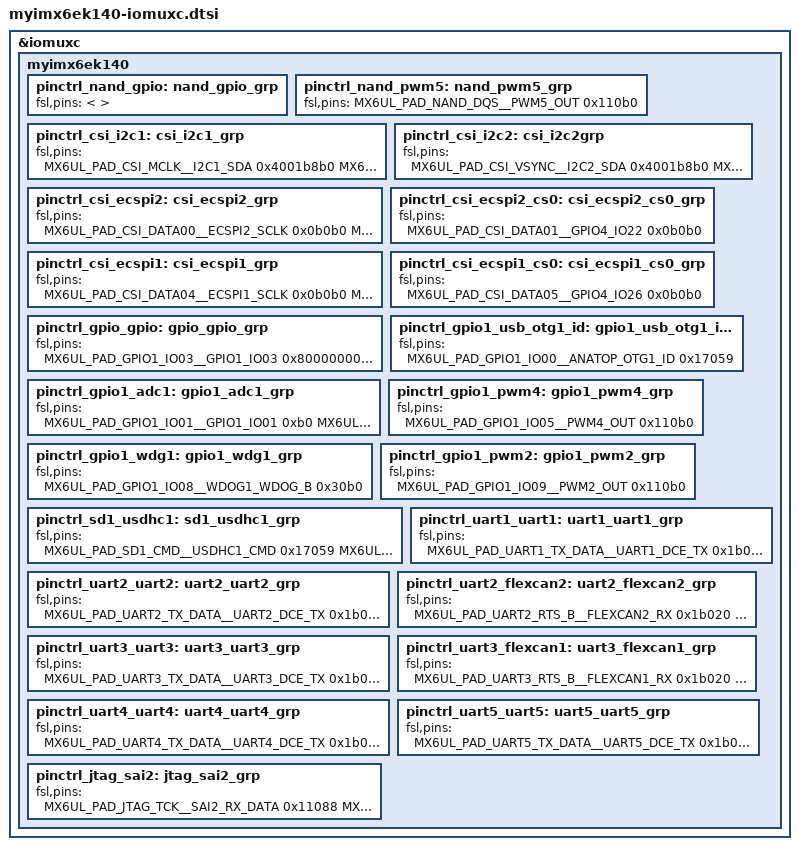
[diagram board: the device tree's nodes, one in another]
/*
 * MYZR Technology Co.,Ltd
 * http://www.myzr.com.cn
 * Tang Bin <tangb@myzr.com.cn>
 */

&iomuxc {
    pinctrl-names = "default";
    myimx6ek140 {
        pinctrl_nand_gpio: nand_gpio_grp {
            fsl,pins = <
                /* MX6UL_PAD_NAND_CE1_B__GPIO4_IO14		0x80000000 */
            >;
        };
        pinctrl_nand_pwm5: nand_pwm5_grp {
            fsl,pins = <
                MX6UL_PAD_NAND_DQS__PWM5_OUT			0x110b0		/* P8:10 */
            >;
        };

        pinctrl_csi_i2c1: csi_i2c1_grp {
            fsl,pins = <
                MX6UL_PAD_CSI_MCLK__I2C1_SDA			0x4001b8b0
                MX6UL_PAD_CSI_PIXCLK__I2C1_SCL			0x4001b8b0
            >;
        };
        pinctrl_csi_i2c2: csi_i2c2grp {
            fsl,pins = <
                MX6UL_PAD_CSI_VSYNC__I2C2_SDA			0x4001b8b0	/* P8:36 */
                MX6UL_PAD_CSI_HSYNC__I2C2_SCL			0x4001b8b0	/* P8:35 */
            >;
        };
        pinctrl_csi_ecspi2: csi_ecspi2_grp {
            fsl,pins = <
                MX6UL_PAD_CSI_DATA00__ECSPI2_SCLK		0x0b0b0		/* P8:27 */
                MX6UL_PAD_CSI_DATA02__ECSPI2_MOSI		0x0b0b0		/* P8:23 */
                MX6UL_PAD_CSI_DATA03__ECSPI2_MISO		0x0b0b0		/* P8:25 */
            >;
        };
        pinctrl_csi_ecspi2_cs0: csi_ecspi2_cs0_grp {
            fsl,pins = <
                MX6UL_PAD_CSI_DATA01__GPIO4_IO22		0x0b0b0		/* P8:29 */
            >;
        };
        pinctrl_csi_ecspi1: csi_ecspi1_grp {
            fsl,pins = <
                MX6UL_PAD_CSI_DATA04__ECSPI1_SCLK 		0x0b0b0		/* P8:28 */
                MX6UL_PAD_CSI_DATA06__ECSPI1_MOSI 		0x0b0b0		/* P8:24 */
                MX6UL_PAD_CSI_DATA07__ECSPI1_MISO 		0x0b0b0		/* P8:26 */
            >;
        };
        pinctrl_csi_ecspi1_cs0: csi_ecspi1_cs0_grp {
            fsl,pins = <
                MX6UL_PAD_CSI_DATA05__GPIO4_IO26		0x0b0b0		/* P8:30 */
            >;
        };

        pinctrl_gpio_gpio: gpio_gpio_grp {
            fsl,pins = <
                MX6UL_PAD_GPIO1_IO03__GPIO1_IO03		0x80000000	/* P8:8 */
                MX6UL_PAD_GPIO1_IO04__GPIO1_IO04		0x80000000	/* P8:5 */
            >;
        };
        pinctrl_gpio1_usb_otg1_id: gpio1_usb_otg1_id_grp {
            fsl,pins = <
                MX6UL_PAD_GPIO1_IO00__ANATOP_OTG1_ID	0x17059
            >;
        };
        pinctrl_gpio1_adc1: gpio1_adc1_grp {
            fsl,pins = <
                MX6UL_PAD_GPIO1_IO01__GPIO1_IO01		0xb0	/* P8:6 */
                MX6UL_PAD_GPIO1_IO02__GPIO1_IO02		0xb0	/* P8:7 */
            >;
        };
        pinctrl_gpio1_pwm4: gpio1_pwm4_grp {
            fsl,pins = <
                MX6UL_PAD_GPIO1_IO05__PWM4_OUT			0x110b0
            >;
        };
        pinctrl_gpio1_wdg1: gpio1_wdg1_grp {
            fsl,pins = <
                MX6UL_PAD_GPIO1_IO08__WDOG1_WDOG_B		0x30b0		/* ADM8320W */
            >;
        };
        pinctrl_gpio1_pwm2: gpio1_pwm2_grp {
            fsl,pins = <
                MX6UL_PAD_GPIO1_IO09__PWM2_OUT			0x110b0		/* P8:9 */
            >;
        };

        pinctrl_sd1_usdhc1: sd1_usdhc1_grp {
            fsl,pins = <
                MX6UL_PAD_SD1_CMD__USDHC1_CMD     		0x17059
                MX6UL_PAD_SD1_CLK__USDHC1_CLK     		0x10059
                MX6UL_PAD_SD1_DATA0__USDHC1_DATA0 		0x17059
                MX6UL_PAD_SD1_DATA1__USDHC1_DATA1 		0x17059
                MX6UL_PAD_SD1_DATA2__USDHC1_DATA2 		0x17059
                MX6UL_PAD_SD1_DATA3__USDHC1_DATA3		0x17059
            >;
        };

        pinctrl_uart1_uart1: uart1_uart1_grp {
            fsl,pins = <
                MX6UL_PAD_UART1_TX_DATA__UART1_DCE_TX	0x1b0b1
                MX6UL_PAD_UART1_RX_DATA__UART1_DCE_RX	0x1b0b1
            >;
        };
        pinctrl_uart2_uart2: uart2_uart2_grp {
            fsl,pins = <
                MX6UL_PAD_UART2_TX_DATA__UART2_DCE_TX	0x1b0b1
                MX6UL_PAD_UART2_RX_DATA__UART2_DCE_RX	0x1b0b1
            >;
        };
        pinctrl_uart2_flexcan2: uart2_flexcan2_grp{
            fsl,pins = <
                MX6UL_PAD_UART2_RTS_B__FLEXCAN2_RX		0x1b020
                MX6UL_PAD_UART2_CTS_B__FLEXCAN2_TX		0x1b020
            >;
        };
        pinctrl_uart3_uart3: uart3_uart3_grp {
            fsl,pins = <
                MX6UL_PAD_UART3_TX_DATA__UART3_DCE_TX	0x1b0b1
                MX6UL_PAD_UART3_RX_DATA__UART3_DCE_RX	0x1b0b1
            >;
        };
        pinctrl_uart3_flexcan1: uart3_flexcan1_grp {
            fsl,pins = <
                MX6UL_PAD_UART3_RTS_B__FLEXCAN1_RX		0x1b020
                MX6UL_PAD_UART3_CTS_B__FLEXCAN1_TX		0x1b020
            >;
        };
        pinctrl_uart4_uart4: uart4_uart4_grp {
            fsl,pins = <
                MX6UL_PAD_UART4_TX_DATA__UART4_DCE_TX	0x1b0b1
                MX6UL_PAD_UART4_RX_DATA__UART4_DCE_RX	0x1b0b1
            >;
        };
        pinctrl_uart5_uart5: uart5_uart5_grp {
            fsl,pins = <
                MX6UL_PAD_UART5_TX_DATA__UART5_DCE_TX	0x1b0b1
                MX6UL_PAD_UART5_RX_DATA__UART5_DCE_RX	0x1b0b1
            >;
        };

        pinctrl_jtag_sai2: jtag_sai2_grp {
            fsl,pins = <
                MX6UL_PAD_JTAG_TCK__SAI2_RX_DATA		0x11088
                MX6UL_PAD_JTAG_TMS__SAI2_MCLK			0x17088
                MX6UL_PAD_JTAG_TDI__SAI2_TX_BCLK		0x17088
                MX6UL_PAD_JTAG_TDO__SAI2_TX_SYNC		0x17088
                MX6UL_PAD_JTAG_TRST_B__SAI2_TX_DATA		0x11088
                MX6UL_PAD_JTAG_MOD__GPIO1_IO10			0x17059		/* P8:17 */
            >;
        };
    };
};
